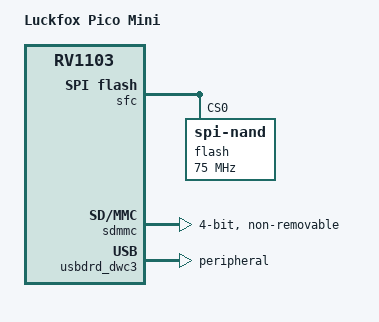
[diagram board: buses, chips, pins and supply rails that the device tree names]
// SPDX-License-Identifier: (GPL-2.0+ OR MIT)
/*
 * Copyright (c) 2023 Luckfox Electronics Co., Ltd.
 */

/dts-v1/;

#include "rv1103.dtsi"
#include "rv1106-evb.dtsi"
#include "rv1103-luckfox-pico-ipc.dtsi"

/ {
	model = "Luckfox Pico Mini";
	compatible = "rockchip,rv1103g-38x38-ipc-v10", "rockchip,rv1103";
};

/**********SFC**********/
&sfc {
	status = "okay";
	flash@0 {
		compatible = "spi-nand";
		reg = <0>;
		spi-max-frequency = <75000000>;
		spi-rx-bus-width = <4>;
		spi-tx-bus-width = <1>;
	};
};

/**********SDMMC**********/
&sdmmc {
	max-frequency = <50000000>;
	no-mmc;
	bus-width = <4>;
	cap-mmc-highspeed;
	cap-sd-highspeed;
	disable-wp;
	
	//sdio
	cap-sdio-irq;
	non-removable;	
	no-1-8-v;
	supports-sdio;

	pinctrl-names = "default";
	pinctrl-0 = <&sdmmc0_clk &sdmmc0_cmd &sdmmc0_det &sdmmc0_bus4>;
	status = "okay";
};

/**********ETH**********/
&gmac {
	status = "disabled";
};

/**********USB**********/
&usbdrd_dwc3 {
	status = "okay";
	dr_mode = "peripheral";
};

/**********SPI**********/
/* SPI0_M0 */
&spi0 {
	status = "disabled";
	spidev@0 {
		spi-max-frequency = <50000000>;
	};
};

/**********I2C**********/
/* I2C3_M1 */
&i2c3 {
	status = "disabled";
	clock-frequency = <100000>;
};

/**********UART**********/
/* UART3_M1 */
&uart3 {
	status = "disabled";
};

/* UART4_M1 */
&uart4 {
	status = "disabled";
};

/**********PWM**********/
/* PWM1_M0 */
&pwm1 {
	status = "disabled";
};
